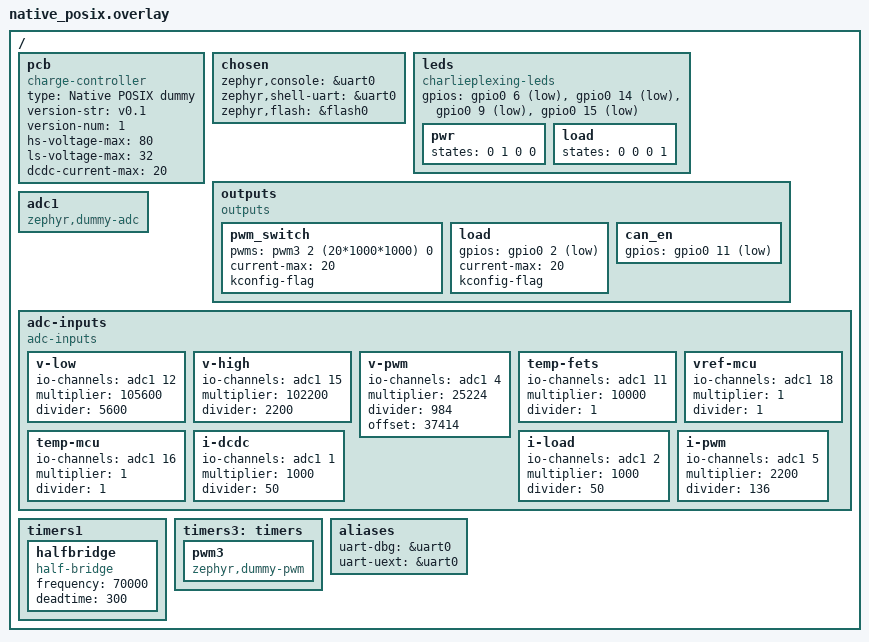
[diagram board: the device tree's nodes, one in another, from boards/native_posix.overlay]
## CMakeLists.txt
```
# Copyright (c) The Libre Solar Project Contributors
# SPDX-License-Identifier: Apache-2.0

set(BOARD_ROOT ${CMAKE_SOURCE_DIR}/..)
set(DTS_ROOT ${CMAKE_SOURCE_DIR}/..)

#set(BOARD "native_posix")
#set(ZEPHYR_TOOLCHAIN_VARIANT "host")

cmake_minimum_required(VERSION 3.13.1)
find_package(Zephyr REQUIRED HINTS $ENV{ZEPHYR_BASE})

project(libre_solar_charge_controller)
add_definitions(-DUNIT_TEST=1)
add_definitions(-DUNITY_OUTPUT_COLOR)
add_definitions(-DUNITY_EXCLUDE_SETJMP)

add_subdirectory(../app/src build/app)

zephyr_include_directories(./src)
zephyr_include_directories(../app/src)

zephyr_include_directories(../../modules/thingset/src)
zephyr_include_directories(../../modules/unity/src)

target_sources(app PRIVATE
        ../../modules/unity/src/unity.c
        src/main.cpp
        src/tests_bat_charger.cpp
        src/tests_daq.cpp
        src/tests_dcdc.cpp
        src/tests_device_status.cpp
        src/tests_load.cpp
        src/tests_power_port.cpp
)

# determine git tag and commit hash for automatic firmware versioning
find_package(Git)
if(GIT_FOUND)
    execute_process(
        COMMAND ${GIT_EXECUTABLE} describe --long --dirty --tags
        OUTPUT_VARIABLE FIRMWARE_VERSION_ID
        OUTPUT_STRIP_TRAILING_WHITESPACE)
else()
    set(FIRMWARE_VERSION_ID "unknown")
endif()
add_definitions(-DFIRMWARE_VERSION_ID="${FIRMWARE_VERSION_ID}")
```

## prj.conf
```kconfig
# Main application configuration (overrides board-specific settings)

# only very small heap necessary for malloc in printf statements with %f
CONFIG_HEAP_MEM_POOL_SIZE=256

CONFIG_CPP=y
CONFIG_REQUIRES_FULL_LIBCPP=y

#CONFIG_WATCHDOG=y
#CONFIG_WDT_DISABLE_AT_BOOT=y
CONFIG_TASK_WDT=y
CONFIG_THREAD_NAME=y

CONFIG_REBOOT=y

CONFIG_HWINFO=y

CONFIG_CONSOLE_SUBSYS=y

CONFIG_LOG=y
CONFIG_LOG_MODE_MINIMAL=y
CONFIG_CBPRINTF_FP_SUPPORT=y

# RNG required for ThingSet node ID generation in native_posix
CONFIG_ENTROPY_GENERATOR=y

CONFIG_THINGSET=y
CONFIG_THINGSET_SDK=y

# ThingSet protocol interface via UART serial
CONFIG_THINGSET_SERIAL=n

# Disable regular data publication on ThingSet serial at startup
CONFIG_THINGSET_REPORTING_LIVE_ENABLE_PRESET=n
```

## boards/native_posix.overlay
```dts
/*
 * Copyright (c) The Libre Solar Project Contributors
 *
 * SPDX-License-Identifier: Apache-2.0
 */

/ {
	/* delete conflicting nodes from Zephyr native_posix board */
	/delete-node/ leds;
	/delete-node/ aliases;

	pcb {
		compatible = "charge-controller";

		type = "Native POSIX dummy";
		version-str = "v0.1";
		version-num = <1>;

		hs-voltage-max = <80>;
		ls-voltage-max = <32>;
		dcdc-current-max = <20>;
	};

	chosen {
		zephyr,console = &uart0;
		zephyr,shell-uart = &uart0;
		zephyr,flash = &flash0;
	};

	leds {
		compatible = "charlieplexing-leds";
		gpios = <&gpio0 6 GPIO_ACTIVE_LOW>,	/* chg red */
			<&gpio0 14 GPIO_ACTIVE_LOW>,	/* chg green */
			<&gpio0 9 GPIO_ACTIVE_LOW>,	/* dis red */
			<&gpio0 15 GPIO_ACTIVE_LOW>;	/* dis green */

		pwr {
			states = <0 1 0 0>;
		};

		load {
			states = <0 0 0 1>;
		};
	};

	outputs {
		compatible = "outputs";

		pwm_switch {
			pwms = <&pwm3 2 (20*1000*1000) 0>; /* 20 ms period = 50 Hz */
			current-max = <20>;
			kconfig-flag;	/* make node visible in Kconfig */
		};

		load {
			gpios = <&gpio0 2 GPIO_ACTIVE_LOW>;
			current-max = <20>;
			kconfig-flag;	/* make node visible in Kconfig */
		};

		can_en {
			gpios = <&gpio0 11 GPIO_ACTIVE_LOW>;
		};
	};

        adc1: adc1 {
		compatible = "zephyr,dummy-adc";
		#io-channel-cells = <1>;
        };

	adc-inputs {
		compatible = "adc-inputs";

		v-low {
			io-channels = <&adc1 12>;
			multiplier = <105600>;
			divider = <5600>;
		};

		v-high {
			io-channels = <&adc1 15>;
			multiplier = <102200>;
			divider = <2200>;
		};

		v-pwm {
			io-channels = <&adc1 4>;
			multiplier = <25224>;	// (12*8.2 + 120*8.2 + 120*12) * 10
			divider = <984>;	// (8.2*12) * 10
			offset = <37414>;	// 65536 / (1 + 8.2/120 + 8.2/12)
		};

		temp-fets {
			io-channels = <&adc1 11>;
			multiplier = <10000>;	// 10k NTC series resistor
			divider = <1>;
		};

		vref-mcu {
			io-channels = <&adc1 18>;
			multiplier = <1>;
			divider = <1>;
		};

		temp-mcu {
			io-channels = <&adc1 16>;
			multiplier = <1>;
			divider = <1>;
		};

		i-dcdc {
			io-channels = <&adc1 1>;
			// amp gain: 25, resistor: 2 mOhm
			multiplier = <1000>;	// 1000
			divider = <50>;	// 2*25
		};

		i-load {
			io-channels = <&adc1 2>;
			// amp gain: 25, resistor: 2 mOhm
			multiplier = <1000>;	// 1000
			divider = <50>;	// 2*25
		};

		i-pwm {
			io-channels = <&adc1 5>;
			// amp gain: 68/2.2, resistor: 2 mOhm
			multiplier = <2200>;	// 1000*2.2
			divider = <136>;	// 2*68
		};
	};

        timers1: timers1 {
                status = "okay";

                halfbridge: halfbridge {
                        compatible = "half-bridge";
                        frequency = <70000>;
                        deadtime = <300>;
                };
        };

	timers3: timers {
		status = "okay";

		pwm3: pwm3 {
                        compatible = "zephyr,dummy-pwm";
			#pwm-cells = <3>;
		};
	};

	aliases {
		uart-dbg = &uart0;
		uart-uext = &uart0;
//		spi-uext = &spi1;
//		i2c-uext = &i2c1;
	};
};
```

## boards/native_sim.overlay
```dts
/*
 * Copyright (c) The Libre Solar Project Contributors
 *
 * SPDX-License-Identifier: Apache-2.0
 */

/ {
	/* delete conflicting nodes from Zephyr native_sim board */
	/delete-node/ leds;
	/delete-node/ aliases;

	pcb {
		compatible = "charge-controller";

		type = "Native POSIX dummy";
		version-str = "v0.1";
		version-num = <1>;

		hs-voltage-max = <80>;
		ls-voltage-max = <32>;
		dcdc-current-max = <20>;
	};

	chosen {
		zephyr,console = &uart0;
		zephyr,shell-uart = &uart0;
		zephyr,flash = &flash0;
	};

	leds {
		compatible = "charlieplexing-leds";
		gpios = <&gpio0 6 GPIO_ACTIVE_LOW>,	/* chg red */
			<&gpio0 14 GPIO_ACTIVE_LOW>,	/* chg green */
			<&gpio0 9 GPIO_ACTIVE_LOW>,	/* dis red */
			<&gpio0 15 GPIO_ACTIVE_LOW>;	/* dis green */

		pwr {
			states = <0 1 0 0>;
		};

		load {
			states = <0 0 0 1>;
		};
	};

	outputs {
		compatible = "outputs";

		pwm_switch {
			pwms = <&pwm3 2 (20*1000*1000) 0>; /* 20 ms period = 50 Hz */
			current-max = <20>;
			kconfig-flag;	/* make node visible in Kconfig */
		};

		load {
			gpios = <&gpio0 2 GPIO_ACTIVE_LOW>;
			current-max = <20>;
			kconfig-flag;	/* make node visible in Kconfig */
		};

		can_en {
			gpios = <&gpio0 11 GPIO_ACTIVE_LOW>;
		};
	};

        adc1: adc1 {
		compatible = "zephyr,dummy-adc";
		#io-channel-cells = <1>;
        };

	adc-inputs {
		compatible = "adc-inputs";

		v-low {
			io-channels = <&adc1 12>;
			multiplier = <105600>;
			divider = <5600>;
		};

		v-high {
			io-channels = <&adc1 15>;
			multiplier = <102200>;
			divider = <2200>;
		};

		v-pwm {
			io-channels = <&adc1 4>;
			multiplier = <25224>;	// (12*8.2 + 120*8.2 + 120*12) * 10
			divider = <984>;	// (8.2*12) * 10
			offset = <37414>;	// 65536 / (1 + 8.2/120 + 8.2/12)
		};

		temp-fets {
			io-channels = <&adc1 11>;
			multiplier = <10000>;	// 10k NTC series resistor
			divider = <1>;
		};

		vref-mcu {
			io-channels = <&adc1 18>;
			multiplier = <1>;
			divider = <1>;
		};

		temp-mcu {
			io-channels = <&adc1 16>;
			multiplier = <1>;
			divider = <1>;
		};

		i-dcdc {
			io-channels = <&adc1 1>;
			// amp gain: 25, resistor: 2 mOhm
			multiplier = <1000>;	// 1000
			divider = <50>;	// 2*25
		};

		i-load {
			io-channels = <&adc1 2>;
			// amp gain: 25, resistor: 2 mOhm
			multiplier = <1000>;	// 1000
			divider = <50>;	// 2*25
		};

		i-pwm {
			io-channels = <&adc1 5>;
			// amp gain: 68/2.2, resistor: 2 mOhm
			multiplier = <2200>;	// 1000*2.2
			divider = <136>;	// 2*68
		};
	};

	halfbridge: halfbridge {
		compatible = "libresolar,half-bridge-emul";
		clock-frequency = <24000000>;
		frequency = <70000>;
		deadtime-ns = <300>;
	};

	timers3: timers {
		status = "okay";

		pwm3: pwm3 {
                        compatible = "zephyr,dummy-pwm";
			#pwm-cells = <3>;
		};
	};

	aliases {
		uart-dbg = &uart0;
		uart-uext = &uart0;
//		spi-uext = &spi1;
//		i2c-uext = &i2c1;
	};
};
```

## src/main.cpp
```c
/*
 * Copyright (c) The Libre Solar Project Contributors
 *
 * SPDX-License-Identifier: Apache-2.0
 */

#include "unity.h"
#include <stdio.h>

#include <zephyr/device.h>
#include <zephyr/kernel.h>

#ifdef CONFIG_ARCH_POSIX
#include "posix_board_if.h"
#endif

#include "tests.h"

extern "C" {

void setUp(void)
{}

void tearDown(void)
{}

} /* extern "C" */

int main()
{
    int err = 0;

    err += daq_tests();
    err += bat_charger_tests();
    err += power_port_tests();
    err += dcdc_tests();
    err += device_status_tests();
    err += load_tests();

#ifdef CONFIG_CUSTOM_TESTS
    err += custom_tests();
#endif

#ifdef CONFIG_ARCH_POSIX
    posix_exit(err);
#endif

    return err;
}
```

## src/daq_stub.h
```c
/*
 * Copyright (c) The Libre Solar Project Contributors
 *
 * SPDX-License-Identifier: Apache-2.0
 */

#ifndef DAQ_STUB_H_
#define DAQ_STUB_H_

/** Data to fill adc_filtered array during unit-tests
 */
typedef struct {
    float solar_voltage;
    float battery_voltage;
    float dcdc_current;
    float load_current;
    float bat_temperature;
    float internal_temperature;
} AdcValues;

void prepare_adc_readings(AdcValues values);

void prepare_adc_filtered();
void clear_adc_filtered();
uint32_t get_adc_filtered(uint32_t channel);
uint16_t adc_raw_clamp(float scale, float limit);

#endif
```

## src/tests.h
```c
/*
 * Copyright (c) The Libre Solar Project Contributors
 *
 * SPDX-License-Identifier: Apache-2.0
 */

#include <time.h>
#include <unity.h>

int bat_charger_tests();

int daq_tests();

int power_port_tests();

int half_bridge_tests();

int dcdc_tests();

int device_status_tests();

int kalman_soc_tests();

int load_tests();

#ifdef CONFIG_CUSTOM_TESTS
int custom_tests();
#endif
```

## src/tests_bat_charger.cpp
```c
/*
 * Copyright (c) The Libre Solar Project Contributors
 *
 * SPDX-License-Identifier: Apache-2.0
 */

#include "tests.h"

#include <stdio.h>
#include <time.h>

#include "setup.h"

static void init_structs()
{
    battery_conf_init(&bat_conf, BAT_TYPE_FLOODED, 6, 100);
    charger.init_terminal(&bat_conf);
    charger.state = CHG_STATE_IDLE;
    charger.bat_temperature = 25;
    bat_terminal.bus->voltage = 14.0;
    bat_terminal.bus->voltage_filtered = 14.0;
    bat_terminal.current = 0;
}

void no_start_at_high_voltage()
{
    init_structs();
    bat_terminal.bus->voltage = bat_conf.recharge_voltage + 0.1f;
    charger.charge_control(&bat_conf);
    TEST_ASSERT_EQUAL(CHG_STATE_IDLE, charger.state);
}

void no_start_after_short_rest()
{
    init_structs();
    charger.time_state_changed = time(NULL) - bat_conf.time_limit_recharge + 1;
    bat_terminal.bus->voltage = bat_conf.recharge_voltage - 0.1f;
    charger.charge_control(&bat_conf);
    TEST_ASSERT_EQUAL(CHG_STATE_IDLE, charger.state);
}

void no_start_outside_temperature_limits()
{
    init_structs();
    charger.bat_temperature = bat_conf.charge_temp_max + 1;
    bat_terminal.bus->voltage = bat_conf.recharge_voltage - 0.1f;
    charger.charge_control(&bat_conf);
    TEST_ASSERT_EQUAL(CHG_STATE_IDLE, charger.state);

    charger.bat_temperature = bat_conf.charge_temp_min - 1;
    charger.charge_control(&bat_conf);
    TEST_ASSERT_EQUAL(CHG_STATE_IDLE, charger.state);
}

void follower_respects_temperature_limits()
{
    init_structs();
    const float temperatures[] = { bat_conf.charge_temp_max + 1,
                                   bat_conf.charge_temp_min - 1 };
    const int errors[] = { ERR_BAT_CHG_OVERTEMP, ERR_BAT_CHG_UNDERTEMP };
    const int states[] = { CHG_STATE_IDLE, CHG_STATE_BULK, CHG_STATE_FOLLOWER };

    for (int state : states) {
        for (int i = 0; i < 2; i++) {
            init_structs();
            charger.state = state;
            charger.bat_temperature = temperatures[i];
            charger.target_current_control = 5;
            charger.time_last_ctrl_msg = time(NULL);

            charger.charge_control(&bat_conf);

            TEST_ASSERT_EQUAL(CHG_STATE_IDLE, charger.state);
            TEST_ASSERT_EQUAL_FLOAT(0, bat_terminal.pos_current_limit);
            TEST_ASSERT_TRUE(dev_stat.has_error(errors[i]));
        }
    }
}

void start_if_everything_just_fine()
{
    init_structs();
    charger.time_state_changed = time(NULL) - bat_conf.time_limit_recharge - 1;
    bat_terminal.bus->voltage = bat_conf.recharge_voltage - 0.1f;
    charger.charge_control(&bat_conf);
    TEST_ASSERT_EQUAL(CHG_STATE_BULK, charger.state);
}

void enter_topping_at_voltage_setpoint()
{
    init_structs();
    charger.time_state_changed = time(NULL) - bat_conf.time_limit_recharge - 1;
    bat_terminal.bus->voltage = bat_conf.recharge_voltage - 0.1f;
    bat_terminal.bus->voltage_filtered = bat_terminal.bus->voltage;
    charger.charge_control(&bat_conf);
    TEST_ASSERT_EQUAL(CHG_STATE_BULK, charger.state);
    bat_terminal.bus->voltage = bat_conf.topping_voltage + 0.1f;
    bat_terminal.bus->voltage_filtered = bat_terminal.bus->voltage;
    charger.charge_control(&bat_conf);
    TEST_ASSERT_EQUAL(CHG_STATE_TOPPING, charger.state);
}

void topping_to_bulk_after_8h_low_power()
{
    enter_topping_at_voltage_setpoint();

    charger.time_state_changed = time(NULL) - 8 * 60 * 60 + 1;
    bat_terminal.bus->voltage = bat_conf.topping_voltage - 0.1f;
    bat_terminal.bus->voltage_filtered = bat_terminal.bus->voltage;
    bat_terminal.current = bat_conf.topping_cutoff_current + 0.1f;
    bat_terminal.current_filtered = bat_terminal.current;

    charger.charge_control(&bat_conf);
    TEST_ASSERT_EQUAL(CHG_STATE_TOPPING, charger.state);

    charger.time_state_changed = time(NULL) - 8 * 60 * 60 - 1;
    charger.charge_control(&bat_conf);
    TEST_ASSERT_EQUAL(CHG_STATE_BULK, charger.state);
}

void stop_topping_after_time_limit()
{
    enter_topping_at_voltage_setpoint();

    charger.target_voltage_timer = bat_conf.topping_duration - 1;
    bat_terminal.current = bat_conf.topping_cutoff_current + 0.1f;
    bat_terminal.current_filtered = bat_terminal.current;
    bat_terminal.bus->voltage =
        bat_conf.topping_voltage - bat_terminal.current * bat_terminal.bus->sink_droop_res + 0.1f;
    bat_terminal.bus->voltage_filtered = bat_terminal.bus->voltage;

    charger.charge_control(&bat_conf);
    TEST_ASSERT_EQUAL(CHG_STATE_TOPPING, charger.state);

    charger.target_voltage_timer = bat_conf.topping_duration + 1;
    charger.charge_control(&bat_conf);
    TEST_ASSERT_EQUAL(CHG_STATE_FLOAT, charger.state);
}

void stop_topping_at_cutoff_current()
{
    enter_topping_at_voltage_setpoint();

    charger.target_voltage_timer = 0;
    bat_terminal.current = bat_conf.topping_cutoff_current - 0.1f;
    bat_terminal.current_filtered = bat_terminal.current;
    bat_terminal.bus->voltage =
        bat_conf.topping_voltage - bat_terminal.current * bat_terminal.bus->sink_droop_res + 0.1f;
    bat_terminal.bus->voltage_filtered = bat_terminal.bus->voltage;
    charger.charge_control(&bat_conf);
    TEST_ASSERT_EQUAL(CHG_STATE_FLOAT, charger.state);
}

void float_to_idle_for_li_ion()
{
    enter_topping_at_voltage_setpoint();
    battery_conf_init(&bat_conf, BAT_TYPE_LFP, 4, 100);

    charger.time_state_changed = time(NULL) - 1;
    bat_terminal.current = bat_conf.topping_cutoff_current - 0.1f;
    bat_terminal.bus->voltage =
        bat_conf.topping_voltage - bat_terminal.current * bat_terminal.bus->sink_droop_res + 0.1f;
    charger.charge_control(&bat_conf);
    TEST_ASSERT_EQUAL(CHG_STATE_IDLE, charger.state);
}

void no_equalization_if_disabled()
{
    enter_topping_at_voltage_setpoint();
    bat_conf.equalization_enabled = false;

    // set triggers such that it would normally start
    charger.deep_dis_last_equalization =
        charger.num_deep_discharges - bat_conf.equalization_trigger_deep_cycles;
    charger.time_last_equalization = time(NULL) - bat_conf.equalization_trigger_days * 24 * 60 * 60;

    charger.time_state_changed = time(NULL) - 1;
    bat_terminal.bus->voltage = bat_conf.topping_voltage + 0.1f;
    bat_terminal.current = bat_conf.topping_cutoff_current - 0.1f;
    charger.charge_control(&bat_conf);
    TEST_ASSERT_NOT_EQUAL(CHG_STATE_EQUALIZATION, charger.state);
}

void no_equalization_if_limits_not_reached()
{
    enter_topping_at_voltage_setpoint();
    bat_conf.equalization_enabled = true;

    // set triggers such that they are just NOT reached
    charger.deep_dis_last_equalization =
        charger.num_deep_discharges - bat_conf.equalization_trigger_deep_cycles + 1;
    charger.time_last_equalization =
        time(NULL) - (bat_conf.equalization_trigger_days - 1) * 24 * 60 * 60;

    charger.time_state_changed = time(NULL) - 1;
    bat_terminal.bus->voltage = bat_conf.topping_voltage + 0.1f;
    bat_terminal.current = bat_conf.topping_cutoff_current - 0.1f;
    charger.charge_control(&bat_conf);
    TEST_ASSERT_NOT_EQUAL(CHG_STATE_EQUALIZATION, charger.state);
}

void float_to_equalization_if_enabled_and_time_limit_reached()
{
    enter_topping_at_voltage_setpoint();
    bat_conf.equalization_enabled = true;
    charger.time_last_equalization = time(NULL) - bat_conf.equalization_trigger_days * 24 * 60 * 60;

    charger.time_state_changed = time(NULL) - 1;
    bat_terminal.current = bat_conf.topping_cutoff_current - 0.1f;
    bat_terminal.bus->voltage =
        bat_conf.topping_voltage - bat_terminal.current * bat_terminal.bus->sink_droop_res + 0.1f;
    charger.charge_control(&bat_conf);
    TEST_ASSERT_EQUAL(CHG_STATE_EQUALIZATION, charger.state);
}

void float_to_equalization_if_enabled_and_deep_dis_limit_reached()
{
    enter_topping_at_voltage_setpoint();
    bat_conf.equalization_enabled = true;
    charger.deep_dis_last_equalization =
        charger.num_deep_discharges - bat_conf.equalization_trigger_deep_cycles;

    charger.time_state_changed = time(NULL) - 1;
    bat_terminal.current = bat_conf.topping_cutoff_current - 0.1f;
    bat_terminal.bus->voltage =
        bat_conf.topping_voltage - bat_terminal.current * bat_terminal.bus->sink_droop_res + 0.1f;
    charger.charge_control(&bat_conf);
    TEST_ASSERT_EQUAL(CHG_STATE_EQUALIZATION, charger.state);
}

void stop_equalization_after_time_limit()
{
    float_to_equalization_if_enabled_and_time_limit_reached();

    charger.time_state_changed = time(NULL) - bat_conf.equalization_duration + 1;
    bat_terminal.bus->voltage = bat_conf.equalization_voltage
                                - bat_terminal.current * bat_terminal.bus->sink_droop_res + 0.1f;

    charger.charge_control(&bat_conf);
    TEST_ASSERT_EQUAL(CHG_STATE_EQUALIZATION, charger.state);

    charger.time_state_changed = time(NULL) - bat_conf.topping_duration - 1;
    charger.charge_control(&bat_conf);
    TEST_ASSERT_EQUAL(CHG_STATE_FLOAT, charger.state);
}

void restart_bulk_from_float_if_voltage_drops()
{
    TEST_ASSERT(0);
}

void stop_discharge_at_low_voltage()
{
    init_structs();

    bat_terminal.bus->voltage = 14;
    charger.discharge_control(&bat_conf);
    TEST_ASSERT_LESS_THAN(0, bat_terminal.neg_current_limit);

    bat_terminal.bus->voltage = bat_conf.absolute_min_voltage - 0.1f;
    charger.discharge_control(&bat_conf);
    TEST_ASSERT_EQUAL(0, bat_terminal.neg_current_limit);
}

void stop_discharge_at_overtemp()
{
    init_structs();
    TEST_ASSERT_LESS_THAN(0, bat_terminal.neg_current_limit);

    charger.bat_temperature = bat_conf.discharge_temp_max + 1;
    charger.discharge_control(&bat_conf);
    TEST_ASSERT_EQUAL(0, bat_terminal.neg_current_limit);
}

void stop_discharge_at_undertemp()
{
    init_structs();
    TEST_ASSERT_LESS_THAN(0, bat_terminal.neg_current_limit);

    charger.bat_temperature = bat_conf.discharge_temp_min - 1;
    charger.discharge_control(&bat_conf);
    TEST_ASSERT_EQUAL(0, bat_terminal.neg_current_limit);
}

void restart_discharge_if_allowed()
{
    init_structs();

    // stop because of undervoltage
    bat_terminal.bus->voltage = bat_conf.absolute_min_voltage - 0.1f;
    charger.discharge_control(&bat_conf);
    TEST_ASSERT_EQUAL(0, bat_terminal.neg_current_limit);

    // increase voltage slightly above absolute minimum
    bat_terminal.bus->voltage = bat_conf.absolute_min_voltage + 0.05f;
    charger.discharge_control(&bat_conf);
    TEST_ASSERT_EQUAL(0, bat_terminal.neg_current_limit);

    // increase voltage above hysteresis voltage
    bat_terminal.bus->voltage = bat_conf.absolute_min_voltage + 0.15f;
    charger.discharge_control(&bat_conf);
    TEST_ASSERT_LESS_THAN(0, bat_terminal.neg_current_limit);
}

void battery_values_propagated_to_lv_bus_int()
{
    TEST_ASSERT(0);
}

void no_soc_above_100()
{
    TEST_ASSERT(0);
}

void no_soc_below_0()
{
    TEST_ASSERT(0);
}

int bat_charger_tests()
{
    UNITY_BEGIN();

    // startup of charging
    RUN_TEST(no_start_at_high_voltage);
    RUN_TEST(no_start_after_short_rest);
    RUN_TEST(no_start_outside_temperature_limits);
    RUN_TEST(follower_respects_temperature_limits);
    RUN_TEST(start_if_everything_just_fine);

    // topping
    RUN_TEST(enter_topping_at_voltage_setpoint);
    RUN_TEST(topping_to_bulk_after_8h_low_power);
    RUN_TEST(stop_topping_after_time_limit);
    RUN_TEST(stop_topping_at_cutoff_current);

    // float
    RUN_TEST(float_to_idle_for_li_ion);

    // equalization
    RUN_TEST(no_equalization_if_disabled);
    RUN_TEST(no_equalization_if_limits_not_reached);
    RUN_TEST(float_to_equalization_if_enabled_and_time_limit_reached);
    RUN_TEST(float_to_equalization_if_enabled_and_deep_dis_limit_reached);
    RUN_TEST(stop_equalization_after_time_limit);

    // RUN_TEST(restart_bulk_from_float_if_voltage_drops);

    // TODO: temperature compensation
    // TODO: current compensation

    RUN_TEST(stop_discharge_at_low_voltage);
    RUN_TEST(stop_discharge_at_overtemp);
    RUN_TEST(stop_discharge_at_undertemp);
    RUN_TEST(restart_discharge_if_allowed);

    // RUN_TEST(battery_values_propagated_to_lv_bus_int);

    // ToDo: SOC calculation
    // RUN_TEST(no_soc_above_100);
    // RUN_TEST(no_soc_below_0);

    return UNITY_END();
}
```

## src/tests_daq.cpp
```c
/*
 * Copyright (c) The Libre Solar Project Contributors
 *
 * SPDX-License-Identifier: Apache-2.0
 */

#include "daq.h"
#include "daq_stub.h"
#include "helper.h"
#include "setup.h"
#include "tests.h"

#include <stdint.h>

static AdcValues adcval;

void test_adc_voltage_to_raw()
{
    int32_t raw;

    raw = adc_voltage_to_raw(0.0, 3300);
    TEST_ASSERT_EQUAL_INT32(0, raw);

    raw = adc_voltage_to_raw(3.3, 3300);
    TEST_ASSERT_EQUAL_INT32(65535, raw);

    raw = adc_voltage_to_raw(1.65, 3300);
    TEST_ASSERT_EQUAL_INT32(32767, raw);
}

void test_adc_raw_to_voltage()
{
    float voltage;

    voltage = adc_raw_to_voltage(0, 3300);
    TEST_ASSERT_EQUAL_FLOAT(0.0, voltage);

    voltage = adc_raw_to_voltage(65535, 3300);
    TEST_ASSERT_FLOAT_WITHIN(0.01, 3.3, voltage);

    voltage = adc_raw_to_voltage(32767, 3300);
    TEST_ASSERT_FLOAT_WITHIN(0.01, 1.65, voltage);
}

// testing only for 2 values
void check_filtering()
{
    // reset values
    clear_adc_filtered();

    // collect 1000 samples to update filtered values
    for (int s = 0; s < 1000; s++) {
        for (int i = 0; i < NUM_ADC_CH; i++) {
            adc_update_value(i);
        }
    }

    uint32_t adc_filtered_bak[NUM_ADC_CH];
    adc_filtered_bak[ADC_POS(vref_mcu)] = get_adc_filtered(ADC_POS(vref_mcu));
    adc_filtered_bak[ADC_POS(v_high)] = get_adc_filtered(ADC_POS(v_high));

    // overwrite filtered values
    prepare_adc_filtered();

    TEST_ASSERT_EQUAL(get_adc_filtered(ADC_POS(vref_mcu)), adc_filtered_bak[ADC_POS(vref_mcu)]);
    TEST_ASSERT_EQUAL(get_adc_filtered(ADC_POS(v_high)), adc_filtered_bak[ADC_POS(v_high)]);
}

void check_solar_terminal_readings()
{
    TEST_ASSERT_EQUAL_FLOAT(adcval.solar_voltage, round(hv_terminal.bus->voltage * 10) / 10);
    TEST_ASSERT_EQUAL_FLOAT(adcval.dcdc_current / adcval.solar_voltage * adcval.battery_voltage,
                            -round(hv_terminal.current * 10) / 10);
}

void check_bat_terminal_readings()
{
    TEST_ASSERT_EQUAL_FLOAT(adcval.battery_voltage, round(lv_terminal.bus->voltage * 10) / 10);
    TEST_ASSERT_EQUAL_FLOAT(adcval.dcdc_current - adcval.load_current,
                            round(lv_terminal.current * 10) / 10);
}

void check_load_terminal_readings()
{
    TEST_ASSERT_EQUAL_FLOAT(adcval.battery_voltage, round(load.bus->voltage * 10) / 10);
    TEST_ASSERT_EQUAL_FLOAT(adcval.load_current, round(load.current * 10) / 10);
}

void check_temperature_readings()
{
    TEST_ASSERT_EQUAL_FLOAT(adcval.bat_temperature, round(charger.bat_temperature * 10) / 10);
}

void adc_alert_lv_undervoltage_triggering()
{
    dev_stat.clear_error(ERR_ANY_ERROR);
    battery_conf_init(&bat_conf, BAT_TYPE_LFP, 4, 100);
    daq_set_lv_limits(bat_conf.absolute_max_voltage, bat_conf.absolute_min_voltage);
    prepare_adc_filtered();
    adc_update_value(ADC_POS(v_low));

    // undervoltage test
    adcval.battery_voltage = bat_conf.absolute_min_voltage - 0.1f;
    prepare_adc_readings(adcval);
    adc_update_value(ADC_POS(v_low));
    TEST_ASSERT_EQUAL(false, dev_stat.has_error(ERR_LOAD_VOLTAGE_DIP));
    adc_update_value(ADC_POS(v_low));
    load.control();
    TEST_ASSERT_EQUAL(true, flags_check(&load.error_flags, ERR_LOAD_VOLTAGE_DIP));
    TEST_ASSERT_EQUAL(LOAD_STATE_OFF, load.state);

    // reset values
    adcval.battery_voltage = 13;
    prepare_adc_readings(adcval);
    prepare_adc_filtered();
    daq_update();

    charger.discharge_control(&bat_conf);
    TEST_ASSERT_EQUAL(false, dev_stat.has_error(ERR_BAT_UNDERVOLTAGE)); // ToDo
}

void adc_alert_lv_overvoltage_triggering()
{
    dev_stat.clear_error(ERR_ANY_ERROR);
    battery_conf_init(&bat_conf, BAT_TYPE_LFP, 4, 100);
    daq_set_lv_limits(bat_conf.absolute_max_voltage, bat_conf.absolute_min_voltage);
    prepare_adc_filtered();
    adc_update_value(ADC_POS(v_low));

    dcdc.state = DCDC_CONTROL_MPPT;

    // overvoltage test
    adcval.battery_voltage = bat_conf.absolute_max_voltage + 0.1f;
    prepare_adc_readings(adcval);
    adc_update_value(ADC_POS(v_low));
    TEST_ASSERT_EQUAL(false, dev_stat.has_error(ERR_BAT_OVERVOLTAGE));
    adc_update_value(ADC_POS(v_low));
    TEST_ASSERT_EQUAL(true, dev_stat.has_error(ERR_BAT_OVERVOLTAGE));
    // TEST_ASSERT_EQUAL(false, pwm_switch.active());
    TEST_ASSERT_EQUAL(DCDC_CONTROL_OFF, dcdc.state);

    // reset values
    adcval.battery_voltage = 12;
    prepare_adc_readings(adcval);
    prepare_adc_filtered();
    daq_update();

    charger.time_state_changed = time(NULL) - bat_conf.time_limit_recharge - 1;
    charger.charge_control(&bat_conf);
    TEST_ASSERT_EQUAL(false, dev_stat.has_error(ERR_BAT_OVERVOLTAGE));
}

void adc_alert_hv_overvoltage_triggering()
{
    dev_stat.clear_error(ERR_ANY_ERROR);
    daq_set_hv_limit(DT_PROP(DT_PATH(pcb), hs_voltage_max));
    prepare_adc_filtered();
    adc_update_value(ADC_POS(v_high));

    // overvoltage test
    adcval.solar_voltage = 85.0F;
    prepare_adc_readings(adcval);
    adc_update_value(ADC_POS(v_high));
    TEST_ASSERT_EQUAL(false, dev_stat.has_error(ERR_DCDC_HS_OVERVOLTAGE));
    adc_update_value(ADC_POS(v_high));
    TEST_ASSERT_EQUAL(true, dev_stat.has_error(ERR_DCDC_HS_OVERVOLTAGE));
    TEST_ASSERT_EQUAL(DCDC_CONTROL_OFF, dcdc.state);
}

void adc_raw_clamp_handles_negative_limits()
{
    TEST_ASSERT_EQUAL_HEX(0, adc_raw_clamp(1.0F, -1.0F));
    TEST_ASSERT_EQUAL_HEX(0, adc_raw_clamp(2.0F, -100.0F));
    TEST_ASSERT_EQUAL_HEX(0, adc_raw_clamp(1.0F, 0.0F));
    TEST_ASSERT_EQUAL_HEX(100, adc_raw_clamp(2.0F, 50.0F));
}

void adc_alert_overflow_prevention()
{
    // try to set an alert that overflows the 12-bit ADC resolution
    uint16_t limit = adc_raw_clamp(1, UINT16_MAX + 1);
    TEST_ASSERT_EQUAL_HEX(UINT16_MAX, limit);
}

/** Data acquisition tests
 *
 * Purpose: Check if raw data from 2 voltage and 2 current measurements are converted
 * to calculated voltage/current measurements of different DC buses
 */
int daq_tests()
{
    adcval.bat_temperature = 25;
    adcval.battery_voltage = 12;
    adcval.dcdc_current = 3;
    adcval.internal_temperature = 25;
    adcval.load_current = 1;
    adcval.solar_voltage = 30;
    prepare_adc_readings(adcval);

    UNITY_BEGIN();

    RUN_TEST(test_adc_voltage_to_raw);
    RUN_TEST(test_adc_raw_to_voltage);

    RUN_TEST(check_filtering);

    // call original daq_update function
    daq_update();

    RUN_TEST(check_solar_terminal_readings);
    RUN_TEST(check_bat_terminal_readings);
    RUN_TEST(check_load_terminal_readings);

    // RUN_TEST(check_temperature_readings);     // TODO

    RUN_TEST(adc_alert_lv_undervoltage_triggering);
    RUN_TEST(adc_alert_lv_overvoltage_triggering);
    RUN_TEST(adc_alert_hv_overvoltage_triggering);
    RUN_TEST(adc_alert_overflow_prevention);
    RUN_TEST(adc_raw_clamp_handles_negative_limits);

    return UNITY_END();
}
```

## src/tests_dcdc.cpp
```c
/*
 * Copyright (c) The Libre Solar Project Contributors
 *
 * SPDX-License-Identifier: Apache-2.0
 */

#include "tests.h"

#include <libresolar/drivers/half_bridge.h>

#include <math.h>
#include <stdio.h>
#include <time.h>

#include "setup.h"

static void init_structs_buck(int num_batteries = 1)
{
    dev_stat.error_flags = 0;
    hv_terminal.init_solar();
    hv_terminal.bus->voltage = 20 * num_batteries;
    hv_terminal.bus->src_voltage_intercept = 18 * num_batteries;
    hv_terminal.bus->series_multiplier = 1;
    hv_terminal.current = 0;
    hv_terminal.update_bus_current_margins();

    battery_conf_init(&bat_conf, BAT_TYPE_GEL, 6, 100);
    charger.port = &lv_terminal;
    charger.init_terminal(&bat_conf);
    lv_terminal.bus->voltage = 14 * num_batteries;
    lv_terminal.bus->series_multiplier = num_batteries;
    lv_terminal.current = 0;
    lv_terminal.update_bus_current_margins();

    dcdc.mode = DCDC_MODE_BUCK;
    dcdc.temp_mosfets = 25;
    dcdc.off_timestamp = 0;
    dcdc.inductor_current = 0;
    dcdc.power = 0;
    dcdc.power_prev = 0;
    dcdc.pwm_direction = 1;
    dcdc.enable = true;
}

static void start_buck()
{
    dev_stat.error_flags = 0;
    init_structs_buck();
    half_bridge_set_duty_limits(dcdc.half_bridge, 12 / dcdc.hs_voltage_max, 0.97);
    half_bridge_set_duty_cycle(dcdc.half_bridge, 0.97);
    dcdc.control();
    dcdc.control();
    dcdc.control(); // call multiple times because of startup delay
    TEST_ASSERT_EQUAL(DCDC_CONTROL_MPPT, dcdc.state);
}

static void init_structs_boost(int num_batteries = 1)
{
    half_bridge_stop(dcdc.half_bridge);

    hv_terminal.init_solar();
    lv_terminal.bus->voltage = 20;
    lv_terminal.bus->src_voltage_intercept = 18;
    lv_terminal.bus->series_multiplier = 1;
    dcdc.inductor_current = 0;
    dcdc.power = 0;
    lv_terminal.update_bus_current_margins();

    int num_cells = (num_batteries == 1) ? 10 : 5;
    battery_conf_init(&bat_conf, BAT_TYPE_NMC, num_cells, 9);
    charger.port = &hv_terminal;
    charger.init_terminal(&bat_conf);
    hv_terminal.bus->voltage = 3.7 * num_cells * num_batteries;
    hv_terminal.bus->series_multiplier = num_batteries;
    hv_terminal.current = 0;
    hv_terminal.power = 0;
    hv_terminal.update_bus_current_margins();

    dcdc.mode = DCDC_MODE_BOOST;
    dcdc.temp_mosfets = 25;
    dcdc.off_timestamp = 0;
    dcdc.power_prev = 0;
    dcdc.pwm_direction = 1;
    dcdc.enable = true;
}

static void start_boost()
{
    init_structs_boost();
    half_bridge_set_duty_limits(dcdc.half_bridge, 12 / dcdc.hs_voltage_max, 0.97);
    half_bridge_set_duty_cycle(dcdc.half_bridge, 0.97);
    dcdc.control();
    dcdc.control();
    dcdc.control(); // call multiple times because of startup delay
    TEST_ASSERT_EQUAL(DCDC_CONTROL_MPPT, dcdc.state);
}

void start_valid_mppt_buck()
{
    init_structs_buck();
    TEST_ASSERT_EQUAL(DCDC_MODE_BUCK, dcdc.check_start_conditions());
}

void start_valid_mppt_buck_dual_battery()
{
    init_structs_buck(2);
    TEST_ASSERT_EQUAL(DCDC_MODE_BUCK, dcdc.check_start_conditions());
}

void start_valid_mppt_boost()
{
    init_structs_boost();
    TEST_ASSERT_EQUAL(DCDC_MODE_BOOST, dcdc.check_start_conditions());
}

void start_valid_mppt_boost_dual_battery()
{
    init_structs_boost(2);
    TEST_ASSERT_EQUAL(DCDC_MODE_BOOST, dcdc.check_start_conditions());
}

void no_start_before_restart_delay()
{
    init_structs_buck();
    dcdc.off_timestamp = time(NULL) - dcdc.restart_interval + 1;
    TEST_ASSERT_EQUAL(DCDC_MODE_OFF, dcdc.check_start_conditions());
    dcdc.off_timestamp = time(NULL) - dcdc.restart_interval;
    TEST_ASSERT_EQUAL(DCDC_MODE_BUCK, dcdc.check_start_conditions());
}

void no_start_if_dcdc_disabled()
{
    init_structs_buck();
    dcdc.enable = false;
    TEST_ASSERT_EQUAL(DCDC_MODE_OFF, dcdc.check_start_conditions());
}

void no_start_if_dcdc_lv_voltage_low()
{
    init_structs_buck();
    lv_terminal.bus->voltage = dcdc.ls_voltage_min - 0.5f;
    TEST_ASSERT_EQUAL(DCDC_MODE_OFF, dcdc.check_start_conditions());
}

// buck

void no_buck_start_if_bat_voltage_high()
{
    init_structs_buck();
    lv_terminal.bus->voltage = bat_conf.topping_voltage + 0.1f;
    TEST_ASSERT_EQUAL(DCDC_MODE_OFF, dcdc.check_start_conditions());
}

void no_buck_start_if_bat_chg_not_allowed()
{
    init_structs_buck();
    lv_terminal.bus->sink_current_margin = 0;
    TEST_ASSERT_EQUAL(DCDC_MODE_OFF, dcdc.check_start_conditions());
}

void no_buck_start_if_solar_voltage_high()
{
    init_structs_buck();
    hv_terminal.bus->voltage = dcdc.hs_voltage_max + 1;
    TEST_ASSERT_EQUAL(DCDC_MODE_OFF, dcdc.check_start_conditions());
}

void no_buck_start_if_solar_voltage_low()
{
    init_structs_buck();
    hv_terminal.bus->voltage = 17;
    TEST_ASSERT_EQUAL(DCDC_MODE_OFF, dcdc.check_start_conditions());
}

// boost

void no_boost_start_if_bat_voltage_high()
{
    init_structs_boost();
    hv_terminal.bus->voltage = bat_conf.topping_voltage + 0.1f;
    TEST_ASSERT_EQUAL(DCDC_MODE_OFF, dcdc.check_start_conditions());
}

void no_boost_start_if_bat_chg_not_allowed()
{
    init_structs_boost();
    hv_terminal.bus->sink_current_margin = 0;
    TEST_ASSERT_EQUAL(DCDC_MODE_OFF, dcdc.check_start_conditions());
}

void no_boost_start_if_solar_voltage_high()
{
    init_structs_boost();
    lv_terminal.bus->voltage = dcdc.ls_voltage_max + 1;
    TEST_ASSERT_EQUAL(DCDC_MODE_OFF, dcdc.check_start_conditions());
}

void no_boost_start_if_solar_voltage_low()
{
    init_structs_boost();
    lv_terminal.bus->voltage = 17;
    TEST_ASSERT_EQUAL(DCDC_MODE_OFF, dcdc.check_start_conditions());
}

// buck operation

void buck_increasing_power()
{
    start_buck();
    float pwm_before = half_bridge_get_duty_cycle(dcdc.half_bridge);
    dcdc.control();
    float pwm_after = half_bridge_get_duty_cycle(dcdc.half_bridge);
    TEST_ASSERT(pwm_after > pwm_before);
}

void buck_derating_output_voltage_too_high()
{
    start_buck();
    float pwm_before = half_bridge_get_duty_cycle(dcdc.half_bridge);
    lv_terminal.bus->voltage = lv_terminal.bus->sink_voltage_intercept + 0.1f;
    dcdc.control();
    float pwm_after = half_bridge_get_duty_cycle(dcdc.half_bridge);
    TEST_ASSERT(pwm_after < pwm_before); // less duty cycle = higher voltage
    TEST_ASSERT_EQUAL(DCDC_CONTROL_CV_LS, dcdc.state);
}

void buck_derating_output_current_too_high()
{
    start_buck();
    float pwm_before = half_bridge_get_duty_cycle(dcdc.half_bridge);
    lv_terminal.current = lv_terminal.pos_current_limit + 0.1f;
    lv_terminal.update_bus_current_margins();
    dcdc.control();
    float pwm_after = half_bridge_get_duty_cycle(dcdc.half_bridge);
    TEST_ASSERT(pwm_after < pwm_before);
    TEST_ASSERT_EQUAL(DCDC_CONTROL_CC_LS, dcdc.state);
}

void buck_derating_inductor_current_too_high()
{
    start_buck();
    float pwm_before = half_bridge_get_duty_cycle(dcdc.half_bridge);
    dcdc.inductor_current = dcdc.inductor_current_max + 0.1f;
    dcdc.control();
    float pwm_after = half_bridge_get_duty_cycle(dcdc.half_bridge);
    TEST_ASSERT(pwm_after < pwm_before);
    TEST_ASSERT_EQUAL(DCDC_CONTROL_CC_LS, dcdc.state);
}

void buck_derating_input_voltage_too_low()
{
    start_buck();
    float pwm_before = half_bridge_get_duty_cycle(dcdc.half_bridge);
    hv_terminal.bus->voltage = hv_terminal.bus->src_voltage_intercept - 0.1f;
    dcdc.power = 1.2f;
    dcdc.control();
    float pwm_after = half_bridge_get_duty_cycle(dcdc.half_bridge);
    TEST_ASSERT(pwm_after < pwm_before);
    TEST_ASSERT_EQUAL(DCDC_CONTROL_CV_HS, dcdc.state);
}

void buck_derating_input_current_too_high()
{
    start_buck();
    float pwm_before = half_bridge_get_duty_cycle(dcdc.half_bridge);
    hv_terminal.current = hv_terminal.neg_current_limit - 0.1f;
    hv_terminal.update_bus_current_margins();
    dcdc.control();
    float pwm_after = half_bridge_get_duty_cycle(dcdc.half_bridge);
    TEST_ASSERT(pwm_after < pwm_before);
    TEST_ASSERT_EQUAL(DCDC_CONTROL_CC_HS, dcdc.state);
}

void buck_derating_temperature_limits_exceeded()
{
    start_buck();
    float pwm_before = half_bridge_get_duty_cycle(dcdc.half_bridge);
    dcdc.temp_mosfets = 81;
    dcdc.control();
    float pwm_after = half_bridge_get_duty_cycle(dcdc.half_bridge);
    TEST_ASSERT(pwm_after < pwm_before);
}

void buck_stop_input_power_too_low()
{
    start_buck();
    dcdc.power_good_timestamp = time(NULL) - 11;
    dcdc.control();
    TEST_ASSERT(half_bridge_is_enabled(dcdc.half_bridge) == false);
}

void buck_stop_high_voltage_emergency()
{
    start_buck();
    lv_terminal.bus->voltage = dcdc.ls_voltage_max + 0.1f;
    dcdc.control();
    TEST_ASSERT(half_bridge_is_enabled(dcdc.half_bridge) == false);
}

void buck_correct_mppt_operation()
{
    start_buck();

    dcdc.power = 5;
    dcdc.control();
    float pwm1 = half_bridge_get_duty_cycle(dcdc.half_bridge);
    dcdc.power = 7;
    dcdc.control();
    float pwm2 = half_bridge_get_duty_cycle(dcdc.half_bridge);
    TEST_ASSERT(pwm2 > pwm1);

    dcdc.power = 6; // decrease power to make the direction turn around
    dcdc.control();
    float pwm3 = half_bridge_get_duty_cycle(dcdc.half_bridge);
    TEST_ASSERT(pwm3 < pwm2);
}

// boost operation

void boost_increasing_power()
{
    // make sure that without changing anything, dcdc_control goes in direction of increasing power
    start_boost();
    float pwm_before = half_bridge_get_duty_cycle(dcdc.half_bridge);
    dcdc.control();
    float pwm_after = half_bridge_get_duty_cycle(dcdc.half_bridge);
    TEST_ASSERT(pwm_after < pwm_before);
}

void boost_derating_output_voltage_too_high()
{
    start_boost();
    float pwm_before = half_bridge_get_duty_cycle(dcdc.half_bridge);
    hv_terminal.bus->voltage = hv_terminal.bus->sink_voltage_intercept + 0.5f;
    dcdc.control();
    float pwm_after = half_bridge_get_duty_cycle(dcdc.half_bridge);
    TEST_ASSERT(pwm_after > pwm_before); // higher duty cycle = less power
}

void boost_derating_output_current_too_high()
{
    start_boost();
    float pwm_before = half_bridge_get_duty_cycle(dcdc.half_bridge);
    hv_terminal.current = hv_terminal.pos_current_limit + 0.1f;
    hv_terminal.update_bus_current_margins();
    dcdc.control();
    float pwm_after = half_bridge_get_duty_cycle(dcdc.half_bridge);
    TEST_ASSERT(pwm_after > pwm_before);
}

void boost_derating_input_voltage_too_low()
{
    start_boost();
    float pwm_before = half_bridge_get_duty_cycle(dcdc.half_bridge);
    lv_terminal.bus->voltage = lv_terminal.bus->src_voltage_intercept - 0.1f;
    dcdc.power = -1.2f;
    hv_terminal.update_bus_current_margins();
    dcdc.control();
    float pwm_after = half_bridge_get_duty_cycle(dcdc.half_bridge);
    TEST_ASSERT_EQUAL(DCDC_CONTROL_CV_LS, dcdc.state);
    TEST_ASSERT(pwm_after > pwm_before);
}

void boost_derating_input_current_too_high()
{
    start_boost();
    float pwm_before = half_bridge_get_duty_cycle(dcdc.half_bridge);
    dcdc.inductor_current = lv_terminal.neg_current_limit - 0.1f;
    dcdc.control();
    float pwm_after = half_bridge_get_duty_cycle(dcdc.half_bridge);
    TEST_ASSERT(pwm_after > pwm_before);
}

void boost_derating_temperature_limits_exceeded()
{
    start_boost();
    float pwm_before = half_bridge_get_duty_cycle(dcdc.half_bridge);
    dcdc.temp_mosfets = 81;
    dcdc.control();
    float pwm_after = half_bridge_get_duty_cycle(dcdc.half_bridge);
    TEST_ASSERT(pwm_after > pwm_before);
}

void boost_stop_input_power_too_low()
{
    start_boost();
    dcdc.power_good_timestamp = time(NULL) - 11;
    dcdc.control();
    TEST_ASSERT(half_bridge_is_enabled(dcdc.half_bridge) == false);
}

void boost_stop_high_voltage_emergency()
{
    start_boost();
    hv_terminal.bus->voltage = dcdc.hs_voltage_max + 0.1f;
    dcdc.control();
    TEST_ASSERT(half_bridge_is_enabled(dcdc.half_bridge) == false);
}

void boost_correct_mppt_operation()
{
    start_boost();

    dcdc.power = -5;
    dcdc.control();
    float pwm1 = half_bridge_get_duty_cycle(dcdc.half_bridge);
    dcdc.power = -7;
    dcdc.control();
    float pwm2 = half_bridge_get_duty_cycle(dcdc.half_bridge);
    TEST_ASSERT(pwm2 < pwm1);

    dcdc.power = -6; // decrease power to make the direction turn around
    dcdc.control();
    float pwm3 = half_bridge_get_duty_cycle(dcdc.half_bridge);
    TEST_ASSERT(pwm3 > pwm2);
}

void fuse_destruction_forces_low_side_on()
{
    start_buck();
    dev_stat.set_error(ERR_DCDC_HS_MOSFET_SHORT);

    // fuse destruction is delayed by 21 calls (seconds) to be able to send out data
    for (int i = 0; i < 21; i++) {
        dcdc.fuse_destruction();
    }
    TEST_ASSERT_NOT_EQUAL(0, half_bridge_get_compare(dcdc.half_bridge));

    dcdc.fuse_destruction();
    TEST_ASSERT_TRUE(half_bridge_is_enabled(dcdc.half_bridge));
    TEST_ASSERT_EQUAL(0, half_bridge_get_compare(dcdc.half_bridge));

    // control loop must not override the forced low side
    dcdc.control();
    TEST_ASSERT_TRUE(half_bridge_is_enabled(dcdc.half_bridge));
    TEST_ASSERT_EQUAL(0, half_bridge_get_compare(dcdc.half_bridge));

    // forced state is restored after the half bridge was stopped
    dcdc.stop();
    dcdc.fuse_destruction();
    TEST_ASSERT_TRUE(half_bridge_is_enabled(dcdc.half_bridge));
    TEST_ASSERT_EQUAL(0, half_bridge_get_compare(dcdc.half_bridge));

    dcdc.stop();
    dev_stat.clear_error(ERR_DCDC_HS_MOSFET_SHORT);
}

int dcdc_tests()
{
    UNITY_BEGIN();

    // 1. Check of general (re)start conditions

    // check if initialization of test is correct and we start at all
    RUN_TEST(start_valid_mppt_buck);
    RUN_TEST(start_valid_mppt_buck_dual_battery);
    RUN_TEST(start_valid_mppt_boost);
    RUN_TEST(start_valid_mppt_boost_dual_battery);

    RUN_TEST(no_start_before_restart_delay);
    RUN_TEST(no_start_if_dcdc_disabled);
    RUN_TEST(no_start_if_dcdc_lv_voltage_low);

    // 2. Check startup for MPPT buck converter scenario

    RUN_TEST(no_buck_start_if_bat_voltage_high);
    RUN_TEST(no_buck_start_if_bat_chg_not_allowed);
    RUN_TEST(no_buck_start_if_solar_voltage_high);
    RUN_TEST(no_buck_start_if_solar_voltage_low);

    // 3. Check startup for MPPT boost converter scenario

    RUN_TEST(no_boost_start_if_bat_voltage_high);
    RUN_TEST(no_boost_start_if_bat_chg_not_allowed);
    RUN_TEST(no_boost_start_if_solar_voltage_high);
    RUN_TEST(no_boost_start_if_solar_voltage_low);

    // 4. Check startup for nanogrid scenario

    // TODO

    // 5. Check DC/DC control after being started

    // buck mode
    RUN_TEST(buck_increasing_power);
    RUN_TEST(buck_derating_output_voltage_too_high);
    RUN_TEST(buck_derating_output_current_too_high);
    RUN_TEST(buck_derating_inductor_current_too_high);
    RUN_TEST(buck_derating_input_voltage_too_low);
    RUN_TEST(buck_derating_input_current_too_high);
    RUN_TEST(buck_derating_temperature_limits_exceeded);
    RUN_TEST(buck_stop_input_power_too_low);
    RUN_TEST(buck_stop_high_voltage_emergency);
    RUN_TEST(buck_correct_mppt_operation);

    // boost mode
    RUN_TEST(boost_increasing_power);
    RUN_TEST(boost_derating_output_voltage_too_high);
    RUN_TEST(boost_derating_output_current_too_high);
    RUN_TEST(boost_derating_input_voltage_too_low);
    RUN_TEST(boost_derating_input_current_too_high);
    RUN_TEST(boost_derating_temperature_limits_exceeded);
    RUN_TEST(boost_stop_input_power_too_low);
    RUN_TEST(boost_stop_high_voltage_emergency);
    RUN_TEST(boost_correct_mppt_operation);

    RUN_TEST(fuse_destruction_forces_low_side_on);

    return UNITY_END();
}
```

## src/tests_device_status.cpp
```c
/*
 * Copyright (c) The Libre Solar Project Contributors
 *
 * SPDX-License-Identifier: Apache-2.0
 */

#include "tests.h"

#include <math.h>
#include <stdio.h>
#include <time.h>

#include "setup.h"

void reset_counters_at_start_of_day()
{
    solar_terminal.bus->voltage = bat_terminal.bus->voltage - 1;

    dev_stat.day_counter = 0;
    dev_stat.solar_power_max_day = 100;
    dev_stat.load_power_max_day = 80;
    dev_stat.solar_power_max_total = 200;
    dev_stat.load_power_max_total = 160;

    solar_terminal.neg_energy_Wh = 10.0;
    bat_terminal.neg_energy_Wh = 3.0;
    bat_terminal.pos_energy_Wh = 4.0;
    load.pos_energy_Wh = 9.0;

    // 5 hours without sun
    for (int i = 0; i <= 5 * 60 * 60; i++) {
        dev_stat.update_energy();
    }

    TEST_ASSERT_EQUAL(10, dev_stat.solar_in_total_Wh);
    TEST_ASSERT_EQUAL(3, dev_stat.bat_dis_total_Wh);
    TEST_ASSERT_EQUAL(4, dev_stat.bat_chg_total_Wh);
    TEST_ASSERT_EQUAL(9, dev_stat.load_out_total_Wh);

    TEST_ASSERT_EQUAL(10, solar_terminal.neg_energy_Wh);
    TEST_ASSERT_EQUAL(3, bat_terminal.neg_energy_Wh);
    TEST_ASSERT_EQUAL(4, bat_terminal.pos_energy_Wh);
    TEST_ASSERT_EQUAL(9, load.pos_energy_Wh);

    // solar didn't come back yet
    TEST_ASSERT_EQUAL(0, dev_stat.day_counter);

    // now solar power comes back
    solar_terminal.bus->voltage = bat_terminal.bus->voltage + 1;
    dev_stat.update_energy();

    // day counter should be increased and daily energy counters reset
    TEST_ASSERT_EQUAL(1, dev_stat.day_counter);
    TEST_ASSERT_EQUAL(0, solar_terminal.neg_energy_Wh);
    TEST_ASSERT_EQUAL(0, bat_terminal.neg_energy_Wh);
    TEST_ASSERT_EQUAL(0, bat_terminal.pos_energy_Wh);
    TEST_ASSERT_EQUAL(0, load.pos_energy_Wh);
    TEST_ASSERT_EQUAL(0, dev_stat.solar_power_max_day);
    TEST_ASSERT_EQUAL(0, dev_stat.load_power_max_day);
    TEST_ASSERT_EQUAL(200, dev_stat.solar_power_max_total);
    TEST_ASSERT_EQUAL(160, dev_stat.load_power_max_total);
}

void dev_stat_new_solar_voltage_max()
{
    solar_terminal.bus->voltage = 40;
    dev_stat.update_min_max_values();
    TEST_ASSERT_EQUAL(40, dev_stat.solar_voltage_max);
}

void dev_stat_new_bat_voltage_max()
{
    bat_terminal.bus->voltage = 31;
    dev_stat.update_min_max_values();
    TEST_ASSERT_EQUAL(31, dev_stat.battery_voltage_max);
}

void dev_stat_new_dcdc_current_max()
{
    dcdc.inductor_current = 21;
    dev_stat.update_min_max_values();
    TEST_ASSERT_EQUAL(21, dev_stat.dcdc_current_max);
}

void dev_stat_new_load_current_max()
{
    load.current = 21;
    dev_stat.update_min_max_values();
    TEST_ASSERT_EQUAL(21, dev_stat.load_current_max);
}

void dev_stat_solar_power_max()
{
    solar_terminal.power = -50;
    dev_stat.update_min_max_values();
    TEST_ASSERT_EQUAL(50, dev_stat.solar_power_max_day);
    TEST_ASSERT_EQUAL(50, dev_stat.solar_power_max_total);
}

void dev_stat_load_power_max()
{
    load.power = 50;
    dev_stat.update_min_max_values();
    TEST_ASSERT_EQUAL(50, dev_stat.load_power_max_day);
    TEST_ASSERT_EQUAL(50, dev_stat.load_power_max_total);
}

void dev_stat_new_mosfet_temp_max()
{
    dcdc.temp_mosfets = 80;
    dev_stat.update_min_max_values();
    TEST_ASSERT_EQUAL(80, dev_stat.mosfet_temp_max);
}

void dev_stat_new_bat_temp_max()
{
    charger.bat_temperature = 45;
    dev_stat.update_min_max_values();
    TEST_ASSERT_EQUAL(45, dev_stat.bat_temp_max);
}

void dev_stat_new_int_temp_max()
{
    dev_stat.int_temp_max = 20;
    dev_stat.internal_temp = 22;
    dev_stat.update_min_max_values();
    TEST_ASSERT_EQUAL(22, dev_stat.int_temp_max);
}

int device_status_tests()
{
    UNITY_BEGIN();

    RUN_TEST(reset_counters_at_start_of_day);

    RUN_TEST(dev_stat_new_solar_voltage_max);
    RUN_TEST(dev_stat_new_bat_voltage_max);
    RUN_TEST(dev_stat_new_dcdc_current_max);
    RUN_TEST(dev_stat_new_load_current_max);
    RUN_TEST(dev_stat_solar_power_max);
    RUN_TEST(dev_stat_load_power_max);
    RUN_TEST(dev_stat_new_mosfet_temp_max);
    RUN_TEST(dev_stat_new_bat_temp_max);
    RUN_TEST(dev_stat_new_int_temp_max);

    return UNITY_END();
}
```
